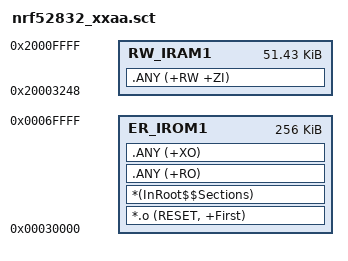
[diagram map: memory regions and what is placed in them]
; *************************************************************
; *** Scatter-Loading Description File generated by uVision ***
; *************************************************************

LR_IROM1 0x00030000 0x00040000  {    ; load region size_region
  ER_IROM1 0x00030000 0x00040000  {  ; load address = execution address
   *.o (RESET, +First)
   *(InRoot$$Sections)
   .ANY (+RO)
   .ANY (+XO)
  }
  RW_IRAM1 0x20003248 0x0000CDB8  {  ; RW data
   .ANY (+RW +ZI)
  }
}
;LR_IROM2 0x00070000 0x00008000 { ; RO section for the VitalSigns Optical Libray
;  ER_IROM2 0x00070000 0x00008000 { ; RO Data load address = execution address
;  fxi_image.o (+RO) 
;  }  
;}

;LR_IROM1 0x00026000 0x0004A000  {    ; load region size_region
;  ER_IROM1 0x00026000 0x0004A000  {  ; load address = execution address
;   *.o (RESET, +First)
;   *(InRoot$$Sections)
;   .ANY (+RO)
;   .ANY (+XO)
;  }
;  RW_IRAM1 0x20002D30 0x0000D2D0  {  ; RW data
;   .ANY (+RW +ZI)
;  }
;}
;LR_IROM2 0x00070000 0x00008000 { ; RO section for the VitalSigns Optical Libray
;  ER_IROM2 0x00070000 0x00008000 { ; RO Data load address = execution address
;  fxi_image.o (+RO) 
;  }  
;}
